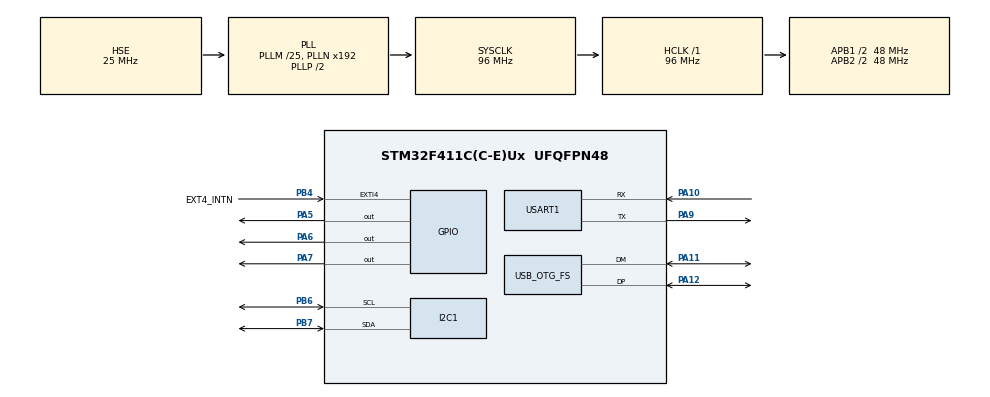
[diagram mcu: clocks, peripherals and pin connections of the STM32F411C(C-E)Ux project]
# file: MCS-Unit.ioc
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Mcu.Family=STM32F4
Mcu.Name=STM32F411C(C-E)Ux
Mcu.Package=UFQFPN48
NVIC.EXTI4_IRQn=true\:0\:0\:false\:false\:true\:true\:true\:true
NVIC.OTG_FS_IRQn=true\:0\:0\:false\:false\:true\:false\:true\:true
NVIC.PriorityGroup=NVIC_PRIORITYGROUP_4
NVIC.USART1_IRQn=true\:0\:0\:false\:false\:true\:true\:true\:true
PA10.Mode=Asynchronous
PA10.Signal=USART1_RX
PA11.Mode=Device_Only
PA11.Signal=USB_OTG_FS_DM
PA12.Mode=Device_Only
PA12.Signal=USB_OTG_FS_DP
PA13.Mode=Serial_Wire
PA13.Signal=SYS_JTMS-SWDIO
PA14.Mode=Serial_Wire
PA14.Signal=SYS_JTCK-SWCLK
PA5.Signal=GPIO_Output
PA6.Signal=GPIO_Output
PA7.Signal=GPIO_Output
PA9.Mode=Asynchronous
PA9.Signal=USART1_TX
PB4.GPIO_Label=EXT4_INTN
PB4.GPIO_PuPd=GPIO_PULLUP
PB4.Signal=GPXTI4
PB6.Mode=I2C
PB6.Signal=I2C1_SCL
PB7.Mode=I2C
PB7.Signal=I2C1_SDA
PH0\ -\ OSC_IN.Mode=HSE-External-Oscillator
PH0\ -\ OSC_IN.Signal=RCC_OSC_IN
PH1\ -\ OSC_OUT.Mode=HSE-External-Oscillator
PH1\ -\ OSC_OUT.Signal=RCC_OSC_OUT
ProjectManager.HeapSize=0x200
ProjectManager.StackSize=0x400
ProjectManager.TargetToolchain=STM32CubeIDE
RCC.48MHZClocksFreq_Value=48000000
RCC.AHBFreq_Value=96000000
RCC.APB1CLKDivider=RCC_HCLK_DIV2
RCC.APB1Freq_Value=48000000
RCC.APB1TimFreq_Value=96000000
RCC.APB2CLKDivider=RCC_HCLK_DIV2
RCC.APB2Freq_Value=48000000
RCC.APB2TimFreq_Value=96000000
RCC.CortexFreq_Value=96000000
RCC.HCLKFreq_Value=96000000
RCC.HSE_VALUE=25000000
RCC.HSI_VALUE=16000000
RCC.LSE_VALUE=32768
RCC.PLLM=25
RCC.SYSCLKFreq_VALUE=96000000
RCC.SYSCLKSource=RCC_SYSCLKSOURCE_PLLCLK
RCC.VCOOutputFreq_Value=192000000
USART1.VirtualMode=VM_ASYNC
USB_DEVICE.CLASS_NAME_FS=CDC
USB_DEVICE.VirtualMode=Cdc
USB_DEVICE.VirtualModeFS=Cdc_FS
USB_OTG_FS.VirtualMode=Device_Only
VP_USB_DEVICE_VS_USB_DEVICE_CDC_FS.Mode=CDC_FS
board=custom

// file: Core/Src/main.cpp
/* USER CODE BEGIN Header */
/**
  ******************************************************************************
  * @file           : main.c
  * @brief          : Main program body
  ******************************************************************************
  * @attention
  *
  * Copyright (c) 2023 STMicroelectronics.
  * All rights reserved.
  *
  * This software is licensed under terms that can be found in the LICENSE file
  * in the root directory of this software component.
  * If no LICENSE file comes with this software, it is provided AS-IS.
  *
  ******************************************************************************
  */
/* USER CODE END Header */
#include "main.h"
#include "usb_device.h"

/* USER CODE BEGIN Includes */
#include "pcap04IIC.h"
#include "pcap04.h"
#include "usbd_cdc_if.h"
/* USER CODE END Includes */

/* USER CODE BEGIN PD */
#define READ_TIMES 20
/* USER CODE END PD */

I2C_HandleTypeDef hi2c1;

UART_HandleTypeDef huart1;

/* USER CODE BEGIN PV */
uint16_t i2c_address = 0x28 << 1;
uint8_t readFlag = 0;
uint8_t readCounter = 0;
float resultArray[3][6][9];
float sum_fine_value, sum_rough_value;

pcap_config_t my_Config_PCAP;
PCAP04IIC my_pcap(pcap04_version_t::PCAP04_V1, pcap_measurement_modes_t::STANDARD, defaultAddress, my_Config_PCAP);

uint8_t RxBuff[30];
/* USER CODE END PV */

void SystemClock_Config(void);
static void MX_GPIO_Init(void);
static void MX_I2C1_Init(void);
static void MX_USART1_UART_Init(void);

int main(void)
{

  /* MCU Configuration--------------------------------------------------------*/

  /* Reset of all peripherals, Initializes the Flash interface and the Systick. */
  HAL_Init();

  /* Configure the system clock */
  SystemClock_Config();

  /* Initialize all configured peripherals */
  MX_GPIO_Init();
  MX_I2C1_Init();
  MX_USART1_UART_Init();
  MX_USB_DEVICE_Init();
  /* USER CODE BEGIN 2 */
  HAL_Delay(1000);
  pcap04_init(&my_pcap, &my_Config_PCAP, i2c_address);

  uint8_t   r0addr = 0x44;
  union {
    uint8_t recval[4];
    uint32_t regval;
  }regdata;
  uint32_t decimal_part, integer_part;
  float decimal_part_f;
  /* USER CODE END 2 */

  /* Infinite loop */
  /* USER CODE BEGIN WHILE */
  while (1)
  {
//    my_pcap.get_status(1);  // enable if debug
//    HAL_I2C_Mem_Read(&hi2c1, 0x28 << 1, r0addr, I2C_MEMADD_SIZE_8BIT, regdata.recval, 4, 0xffff);
//    decimal_part = regdata.regval & 0x07FFFFFF;
//    integer_part = regdata.regval >> 27;
//    decimal_part_f =  integer_part + (float)(decimal_part/134217727.0f)*0.9999995f;
//    usb_printf("%c%c%c%c\n", regdata.recval[0], regdata.recval[1], regdata.recval[2], regdata.recval[3]);
//    usb_printf("data=%.5f\n", decimal_part_f);
    HAL_Delay(10);

    if(readFlag){
      HAL_GPIO_TogglePin(LED_GPIO_Port, LED_Pin);
      HAL_NVIC_DisableIRQ(EXTI4_IRQn);
      readFlag = 0;
      pcap04_updateResults(&my_pcap, 0);
      printResults();
//      sum_fine_value += getCh1value();
//      sum_rough_value += getCh2value();
      HAL_NVIC_EnableIRQ(EXTI4_IRQn);
    }
//    if(readCounter >= READ_TIMES){
//      readCounter = 0;
////      usb_printf("output:%.4f,%.4f\r\n", sum_fine_value/READ_TIMES, sum_rough_value/READ_TIMES);
//      sum_fine_value = 0;
//      sum_rough_value = 0;
//    }

    /* USER CODE END WHILE */

    /* USER CODE BEGIN 3 */
  }
  /* USER CODE END 3 */ }

void SystemClock_Config(void)
{
  RCC_OscInitTypeDef RCC_OscInitStruct = {0};
  RCC_ClkInitTypeDef RCC_ClkInitStruct = {0};

  /** Configure the main internal regulator output voltage
  */
  __HAL_RCC_PWR_CLK_ENABLE();
  __HAL_PWR_VOLTAGESCALING_CONFIG(PWR_REGULATOR_VOLTAGE_SCALE1);

  /** Initializes the RCC Oscillators according to the specified parameters
  * in the RCC_OscInitTypeDef structure.
  */
  RCC_OscInitStruct.OscillatorType = RCC_OSCILLATORTYPE_HSE;
  RCC_OscInitStruct.HSEState = RCC_HSE_ON;
  RCC_OscInitStruct.PLL.PLLState = RCC_PLL_ON;
  RCC_OscInitStruct.PLL.PLLSource = RCC_PLLSOURCE_HSE;
  RCC_OscInitStruct.PLL.PLLM = 25;
  RCC_OscInitStruct.PLL.PLLN = 192;
  RCC_OscInitStruct.PLL.PLLP = RCC_PLLP_DIV2;
  RCC_OscInitStruct.PLL.PLLQ = 4;
  if (HAL_RCC_OscConfig(&RCC_OscInitStruct) != HAL_OK)
  {
    Error_Handler();
  }

  /** Initializes the CPU, AHB and APB buses clocks
  */
  RCC_ClkInitStruct.ClockType = RCC_CLOCKTYPE_HCLK|RCC_CLOCKTYPE_SYSCLK
                              |RCC_CLOCKTYPE_PCLK1|RCC_CLOCKTYPE_PCLK2;
  RCC_ClkInitStruct.SYSCLKSource = RCC_SYSCLKSOURCE_PLLCLK;
  RCC_ClkInitStruct.AHBCLKDivider = RCC_SYSCLK_DIV1;
  RCC_ClkInitStruct.APB1CLKDivider = RCC_HCLK_DIV2;
  RCC_ClkInitStruct.APB2CLKDivider = RCC_HCLK_DIV2;

  if (HAL_RCC_ClockConfig(&RCC_ClkInitStruct, FLASH_LATENCY_3) != HAL_OK)
  {
    Error_Handler();
  }
}

static void MX_I2C1_Init(void)
{

  hi2c1.Instance = I2C1;
  hi2c1.Init.ClockSpeed = 100000;
  hi2c1.Init.DutyCycle = I2C_DUTYCYCLE_2;
  hi2c1.Init.OwnAddress1 = 0;
  hi2c1.Init.AddressingMode = I2C_ADDRESSINGMODE_7BIT;
  hi2c1.Init.DualAddressMode = I2C_DUALADDRESS_DISABLE;
  hi2c1.Init.OwnAddress2 = 0;
  hi2c1.Init.GeneralCallMode = I2C_GENERALCALL_DISABLE;
  hi2c1.Init.NoStretchMode = I2C_NOSTRETCH_DISABLE;
  if (HAL_I2C_Init(&hi2c1) != HAL_OK)
  {
    Error_Handler();
  }

}

static void MX_USART1_UART_Init(void)
{

  huart1.Instance = USART1;
  huart1.Init.BaudRate = 115200;
  huart1.Init.WordLength = UART_WORDLENGTH_8B;
  huart1.Init.StopBits = UART_STOPBITS_1;
  huart1.Init.Parity = UART_PARITY_NONE;
  huart1.Init.Mode = UART_MODE_TX_RX;
  huart1.Init.HwFlowCtl = UART_HWCONTROL_NONE;
  huart1.Init.OverSampling = UART_OVERSAMPLING_16;
  if (HAL_UART_Init(&huart1) != HAL_OK)
  {
    Error_Handler();
  }

}

static void MX_GPIO_Init(void)
{
    GPIO_InitTypeDef GPIO_InitStruct = {0};

    /* GPIO Ports Clock Enable */
    __HAL_RCC_GPIOH_CLK_ENABLE();
    __HAL_RCC_GPIOA_CLK_ENABLE();
    __HAL_RCC_GPIOB_CLK_ENABLE();

    /*Configure GPIO pin Output Level */
    HAL_GPIO_WritePin(LED_GPIO_Port, LED_Pin, GPIO_PIN_RESET);

    /*Configure GPIO pin : LED_Pin */
    GPIO_InitStruct.Pin = LED_Pin;
    GPIO_InitStruct.Mode = GPIO_MODE_OUTPUT_PP;
    GPIO_InitStruct.Pull = GPIO_NOPULL;
    GPIO_InitStruct.Speed = GPIO_SPEED_FREQ_LOW;
    HAL_GPIO_Init(LED_GPIO_Port, &GPIO_InitStruct);

    /*Configure GPIO pin : EXT4_INTN_Pin */
    GPIO_InitStruct.Pin = EXT4_INTN_Pin;
    GPIO_InitStruct.Mode = GPIO_MODE_IT_RISING;
    GPIO_InitStruct.Pull = GPIO_PULLUP;
    HAL_GPIO_Init(EXT4_INTN_GPIO_Port, &GPIO_InitStruct);

    /* EXTI interrupt init*/
    HAL_NVIC_SetPriority(EXTI4_IRQn, 0, 0);
    HAL_NVIC_EnableIRQ(EXTI4_IRQn);

}

/* USER CODE BEGIN 4 */
void HAL_GPIO_EXTI_Callback(uint16_t GPIO_Pin){
    if(GPIO_Pin == GPIO_PIN_4){
        readFlag = 1;
        readCounter++;
    }
}

void HAL_UART_RxCpltCallback(UART_HandleTypeDef *huart)
{
//  if(huart == &huart1)
//  {
//    usb_printf("From Core:%c", RxBuff[2]);
//    HAL_UART_Receive_IT(&huart1, RxBuff, 10);
//  }
}
/* USER CODE END 4 */

void Error_Handler(void)
{
  __disable_irq();
  while (1)
  {
  }
}
